# EFM32G800F128 register map
File version: 5.2.1
Silicon Labs EFM32G800F128 Cortex-M MCU
Registers are 32-bit, read-write, reset 0x0 unless marked. A register's access mark holds for its fields unless they carry their own. Offsets are from the block's base; lines under a group give offsets from that group; [hi:lo] are bit positions; {n}, {i} and the like mark numbered series; 'fields as' and 'values as' point back to an identical list; <NAME> marks a mode.

## Memory map
0x40000000 VCMP size 0x400
0x40001000 ACMP0 size 0x400
0x40001400 ACMP1 size 0x400
0x40002000 ADC0 size 0x400
0x40004000 DAC0 size 0x400
0x40006000 GPIO size 0x1000
0x40008000 EBI size 0x400
0x4000A000 I2C0 size 0x400
0x4000C000 USART0 size 0x400
0x4000C400 USART1 size 0x400
0x4000C800 USART2 size 0x400
0x4000E000 UART0 size 0x400
0x40010000 TIMER0 size 0x400
0x40010400 TIMER1 size 0x400
0x40010800 TIMER2 size 0x400
0x40080000 RTC size 0x400
0x40082000 LETIMER0 size 0x400
0x40084000 LEUART0 size 0x400
0x40084400 LEUART1 size 0x400
0x40086000 PCNT0 size 0x400
0x40086400 PCNT1 size 0x400
0x40086800 PCNT2 size 0x400
0x40088000 WDOG size 0x400
0x4008A000 LCD size 0x400
0x400C0000 MSC size 0x400
0x400C2000 DMA size 0x2000
0x400C6000 EMU size 0x400
0x400C8000 CMU size 0x400
0x400CA000 RMU size 0x400
0x400CC000 PRS size 0x400
0x400E0000 AES size 0x400

## Interrupts
0 DMA
1 GPIO_EVEN (GPIO)
2 TIMER0
3 USART0_RX (USART0)
4 USART0_TX (USART0)
5 ACMP0 (ACMP0, ACMP1)
6 ADC0
7 DAC0
8 I2C0
9 GPIO_ODD (GPIO)
10 TIMER1
11 TIMER2
12 USART1_RX (USART1)
13 USART1_TX (USART1)
14 USART2_RX (USART2)
15 USART2_TX (USART2)
16 UART0_RX (UART0)
17 UART0_TX (UART0)
18 LEUART0
19 LEUART1
20 LETIMER0
21 PCNT0
22 PCNT1
23 PCNT2
24 RTC
25 CMU
26 VCMP
27 LCD
28 MSC
29 AES

## Further device data
name=(C) Copyright Silicon Laboratories, Inc. 2015

## AES
Base 0x400E0000
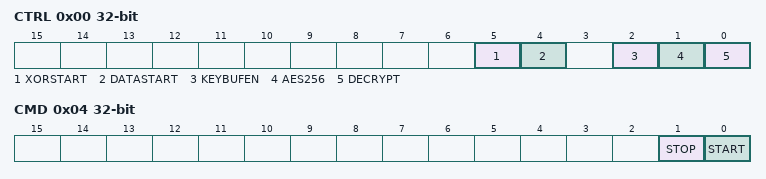
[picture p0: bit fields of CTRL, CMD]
0x00 CTRL — Control Register
  [5] XORSTART — AES_XORDATA Write Start
  [4] DATASTART — AES_DATA Write Start
  [2] KEYBUFEN — Key Buffer Enable
  [1] AES256 — AES-256 Mode
  [0] DECRYPT — Decryption/Encryption Mode
0x04 CMD wo — Command Register
  [1] STOP — Encryption/Decryption Stop
  [0] START — Encryption/Decryption Start
0x08 STATUS ro
  [0] RUNNING — AES Running
0x0C IEN — Interrupt Enable Register
  [0] DONE — Encryption/Decryption Done Interrupt Enable
0x10 IF ro — Interrupt Flag Register
  [0] DONE — Encryption/Decryption Done Interrupt Flag
0x14 IFS wo — Interrupt Flag Set Register
  [0] DONE — Encryption/Decryption Done Interrupt Flag Set
0x18 IFC wo — Interrupt Flag Clear Register
  [0] DONE — Encryption/Decryption Done Interrupt Flag Clear
0x1C DATA read-has-side-effects
  [31:0] DATA — Data Access
0x20 XORDATA read-has-side-effects
  [31:0] XORDATA — XOR Data Access
0x30 KEYLA read-has-side-effects — KEY Low Register
  [31:0] KEYLA — Key Low Access A
0x34 KEYLB read-has-side-effects — KEY Low Register
  [31:0] KEYLB — Key Low Access B
0x38 KEYLC read-has-side-effects — KEY Low Register
  [31:0] KEYLC — Key Low Access C
0x3C KEYLD read-has-side-effects — KEY Low Register
  [31:0] KEYLD — Key Low Access D
0x40 KEYHA read-has-side-effects — KEY High Register
  [31:0] KEYHA — Key High Access A
0x44 KEYHB read-has-side-effects — KEY High Register
  [31:0] KEYHB — Key High Access B
0x48 KEYHC read-has-side-effects — KEY High Register
  [31:0] KEYHC — Key High Access C
0x4C KEYHD read-has-side-effects — KEY High Register
  [31:0] KEYHD — Key High Access D

## MSC
Base 0x400C0000
0x00 CTRL reset 0x1 — Memory System Control Register
  [0] BUSFAULT — Bus Fault Response Enable
0x04 READCTRL reset 0x1 — Read Control Register
  [2:0] MODE — Read Mode
    0=WS0 (Zero wait-states inserted in fetch or read transfers.); 1=WS1 (One wait-state inserted for each fetch or read transfer. This mode is required for a core frequency above 16 MHz.); 2=WS0SCBTP (Zero wait-states inserted with the Suppressed Conditional Branch Target Prefetch (SCBTP) function enabled. SCBTP saves energy by delaying the Cortex' conditional branch target prefetches until the conditional branch instruction is in the execute stage. When the instruction reaches this stage, the evaluation of the branch condition is completed and the core does not perform a speculative prefetch of both the branch target address and the next sequential address. With the SCBTP function enabled, one instruction fetch is saved for each branch not taken, with a negligible performance penalty.); 3=WS1SCBTP (One wait-state access with SCBTP enabled.)
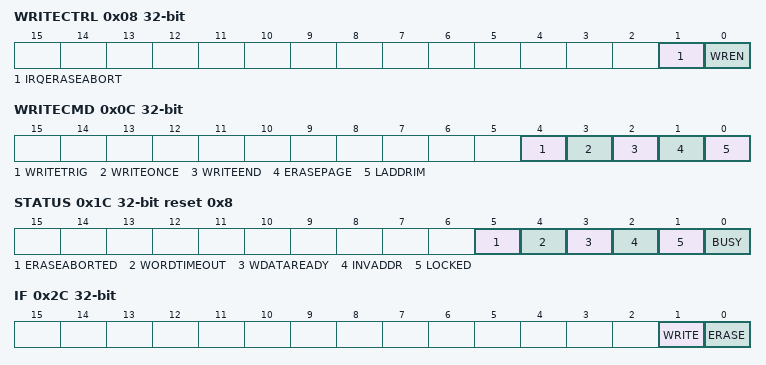
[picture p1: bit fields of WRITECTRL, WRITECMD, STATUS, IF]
0x08 WRITECTRL — Write Control Register
  [1] IRQERASEABORT — Abort Page Erase on Interrupt
  [0] WREN — Enable Write/Erase Controller
0x0C WRITECMD wo — Write Command Register
  [4] WRITETRIG — Word Write Sequence Trigger
  [3] WRITEONCE — Word Write-Once Trigger
  [2] WRITEEND — End Write Mode
  [1] ERASEPAGE
  [0] LADDRIM — Load MSC_ADDRB into ADDR
0x10 ADDRB — Page Erase/Write Address Buffer
  [31:0] ADDRB — Page Erase or Write Address Buffer
0x18 WDATA — Write Data Register
  [31:0] WDATA — Write Data
0x1C STATUS ro reset 0x8
  [5] ERASEABORTED — The Current Flash Erase Operation Aborted
  [4] WORDTIMEOUT — Flash Write Word Timeout
  [3] WDATAREADY — WDATA Write Ready
  [2] INVADDR — Invalid Write Address or Erase Page
  [1] LOCKED — Access Locked
  [0] BUSY — Erase/Write Busy
0x2C IF ro — Interrupt Flag Register
  [1] WRITE — Write Done Interrupt Read Flag
  [0] ERASE — Erase Done Interrupt Read Flag
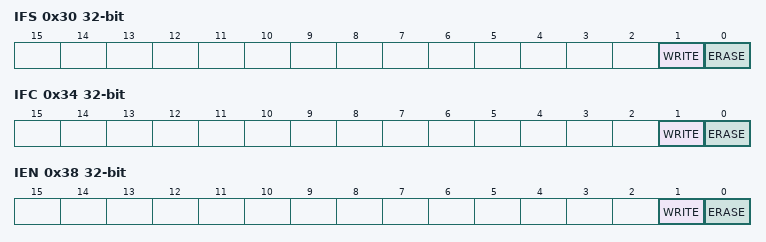
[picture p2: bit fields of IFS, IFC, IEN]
0x30 IFS wo — Interrupt Flag Set Register
  [1] WRITE — Write Done Interrupt Set
  [0] ERASE — Erase Done Interrupt Set
0x34 IFC wo — Interrupt Flag Clear Register
  [1] WRITE — Write Done Interrupt Clear
  [0] ERASE — Erase Done Interrupt Clear
0x38 IEN — Interrupt Enable Register
  [1] WRITE — Write Done Interrupt Enable
  [0] ERASE — Erase Done Interrupt Enable
0x3C LOCK — Configuration Lock Register
  [15:0] LOCKKEY — Configuration Lock
    0=UNLOCKED; 1=LOCKED
